# STM32MP25_CM33 register map
File version: 1.3
CPU: CM33 r0p1, little endian, MPU, FPU, vendor SysTick, 8 interrupt priority bits
Registers are 32-bit, read-write, reset 0x0 unless marked. A register's access mark holds for its fields unless they carry their own. Offsets are from the block's base; [hi:lo] are bit positions; lines under a group give offsets from that group; {n}, {i} and the like mark numbered series; 'fields as' and 'values as' point back to an identical list.

## DDRPHYC (part 2 of 2) — DDRPHYC address block description
Base 0x48C00000
Same registers: DDRPHYC_S 0x58C00000
0x80170 DDRPHYC_MASTER0_MEMALERTCONTROL2 — DDRPHYC MemAlert receiver configuration register 2
  [0] MALERTSYNCBYPASS — This bit is programmed as follows:
    0=The phy drives dfi_alert_n with a synchronized value of the ALERT_N receiver; 1=The phy drives dfi_alert_n with the asynchronous value of the ALERT_N receiver
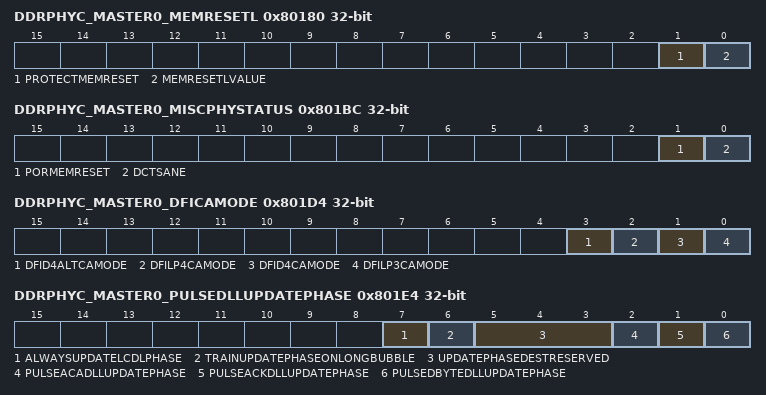
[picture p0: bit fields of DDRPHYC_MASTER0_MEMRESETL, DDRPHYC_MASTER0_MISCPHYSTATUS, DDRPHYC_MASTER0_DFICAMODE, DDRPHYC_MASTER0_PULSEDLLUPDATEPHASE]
0x80180 DDRPHYC_MASTER0_MEMRESETL — DDRPHYC protection and control of BP_MemReset_L register
  [1] PROTECTMEMRESET — Controls the MemResetL output of the PHY.
  [0] MEMRESETLVALUE — Controls the MemResetL output of the PHY.
0x801B8 DDRPHYC_MASTER0_PUBMODE — DDRPHYC PUBMODE - HWT Mux select register
  [0] HWTMEMSRC — When this bit is set, the mux that switches between DCT and HWT for the source of memory transactions is switched to HWT.
    0=Control to the DCT; 1=Control to the HWT
0x801BC DDRPHYC_MASTER0_MISCPHYSTATUS ro reset not defined — DDRPHYC misc PHY status bits register
  [1] PORMEMRESET — Returns the active-high value used by the custom circuit which drives the memory reset signal.
  [0] DCTSANE — Returns the status of the custom circuit which protects the MemResetL output of the PHY on the initial power-on or reset.
    0=Hardware controls the MemResetL output; 1=The memory reset is being controlled by MEMRESESETLVALUE and ProtectMemReset or dfi_reset_n
0x801C0 DDRPHYC_MASTER0_CORELOOPBACKSEL — DDRPHYC CoreLoopbackSel register
  [0] CORELOOPBACKSEL — This bit is controlled by the PHY test firmware.
0x801C4 DDRPHYC_MASTER0_DLLTRAINPARAM reset 0x2 — DDRPHYC DLL various training parameters register
  [1:0] EXTENDPHDTIME — Used by the PHY firmware locking the LCDL delay cells
0x801D0 DDRPHYC_MASTER0_HWTLPCSENBYPASS — DDRPHYC HwtLpCsEnBypass register
  [0] HWTLPCSENBYPASS — When set, this bit disables LpCsEn function for LPDDR4.
0x801D4 DDRPHYC_MASTER0_DFICAMODE — DDRPHYC DFI command/address mode register
  [3] DFID4ALTCAMODE — DDR4-Alt mode enable (only available in certain configurations)
    0=D4-Alt mode disabled; 1=D4-Alt mode enabled
  [2] DFILP4CAMODE — LP4 mode enable
    0=LP4 mode disabled; 1=LP4 mode enabled
  [1] DFID4CAMODE — DDR4 mode enable
    0=D4 mode disabled; 1=D4 mode enabled
  [0] DFILP3CAMODE — Reserved, must be kept at reset value.
0x801E0 DDRPHYC_MASTER0_DLLCONTROL reset 0x3 — DDRPHYC DLL lock state machine control register
  [0] DLLRESETRELOCK — Used to reset the DDL/LCDL lock state machine
0x801E4 DDRPHYC_MASTER0_PULSEDLLUPDATEPHASE — DDRPHYC DLL update phase control register
  [7] ALWAYSUPDATELCDLPHASE — Causes each new operation to reload the LcdlPhase, and increases bubbles.
  [6] TRAINUPDATEPHASEONLONGBUBBLE — Causes LongBubble to update the DBYTE and ANIB LDCL phase.
  [5:3] UPDATEPHASEDESTRESERVED — reserved, not used
  [2] PULSEACADLLUPDATEPHASE — Causes an AC module CA (command/address/cke/odt) DLL phase update.
  [1] PULSEACKDLLUPDATEPHASE — Causes an AC module CK (memck) DLL phase update.
  [0] PULSEDBYTEDLLUPDATEPHASE — Causes a LongBubble to the DBYTE modules, which causes an update of the DBYTE module DLLs (tx,rxen,rxclk).
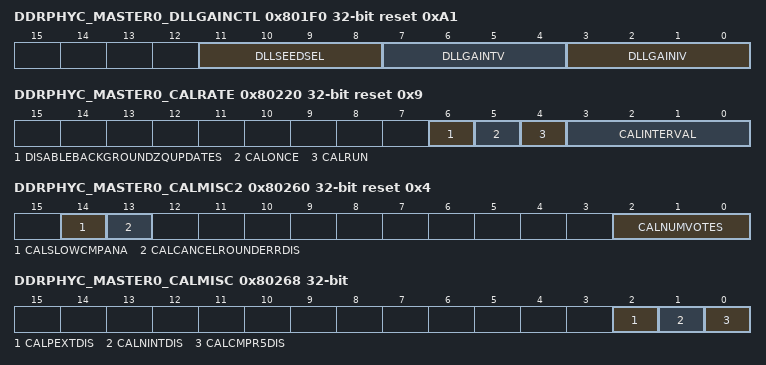
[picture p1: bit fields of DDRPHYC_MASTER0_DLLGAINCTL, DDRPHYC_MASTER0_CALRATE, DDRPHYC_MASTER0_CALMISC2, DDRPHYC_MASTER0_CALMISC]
0x801F0 DDRPHYC_MASTER0_DLLGAINCTL reset 0xA1 — DDRPHYC DLL gain control register
  [11:8] DLLSEEDSEL — Reserved, must be configured to be 0.
  [7:4] DLLGAINTV — Terminal value of DllGain (value in effect when locking is done), and value used for maintaining lock (tracking pclk variation)
  [3:0] DLLGAINIV — Initial value of DllGain
0x80220 DDRPHYC_MASTER0_CALRATE reset 0x9 — DDRPHYC impedance calibration control register
  [6] DISABLEBACKGROUNDZQUPDATES — Reserved for debug only
  [5] CALONCE — The setting of this bit changes the behavior of CALRUN.
    0=The calibration proceeds at the rate determined by CALINTERVAL[3:0]; 1=The 0->1 transition of CALRUN causes a single iteration of the calibration sequence to occur
  [4] CALRUN — This bit is programmed as follows:
    0=The calibrator does not run; 1=A calibration sequence is triggered by the 0->1 transition of this bit, as determined by CALONCE
  [3:0] CALINTERVAL — Interval between successive calibrations
    0=0 ms (continuous); 1=0; 2=0; 3=1 ms; 4=2 ms; 6=4 ms; 7=8 ms; 8=10 ms; 9=20 ms
0x80224 DDRPHYC_MASTER0_CALZAP — DDRPHYC CalZap register
  [0] CALZAP — This bit is written by the PIE, and the data in here are overwritten.
0x8022C DDRPHYC_MASTER0_PSTATE reset 0xC — DDRPHYC PState register
  [3:0] PSTATE — This bit field is written by the PIE, and the data in here are overwritten.
    0=PState P0; 12=LP2; 15=LP3
0x80234 DDRPHYC_MASTER0_PLLOUTGATECONTROL — DDRPHYC PLL output control register
  [0] PCLKGATEEN — Reserved.
0x80240 DDRPHYC_MASTER0_PORCONTROL — DDRPHYC PMU power-on reset control register
  [0] PLLDLLLOCKDONE — This bit is set by the PIE during execution, and cleared on PHY reset, or on power cycle.
0x8025C DDRPHYC_MASTER0_CALBUSY ro reset not defined — DDRPHYC CalBusy register
  [0] CALBUSY — Read 1 if the calibrator is actively calibrating.
0x80260 DDRPHYC_MASTER0_CALMISC2 reset 0x4 — DDRPHYC misc impedance calibration control register
  [14] CALSLOWCMPANA — When set, this bit doubles the time allowed for the analog comparator cell to settle before sampling begins.
  [13] CALCANCELROUNDERRDIS — The PEXT and NINT calibration results naturally include a rounding error which manifests as a change of impedance at the pad.
  [2:0] CALNUMVOTES — This bit field controls the number of consecutive comparator output bits over which majority voting is done.
    0=1; 1=9; 2=17; 3=33; 4=65 (default); 5=129; 6=193; 7=255
0x80268 DDRPHYC_MASTER0_CALMISC — DDRPHYC controls for disabling the impedance calibration of certain target register
  [2] CALPEXTDIS — Setting this bit prevents the calibration engine from overwriting TXCALBINP and TXCALTHP with an automatically generated value, in which case a value must be supplied by software.
  [1] CALNINTDIS — Setting this bit prevents the calibration engine from overwriting TXCALBIN and TXCALTHN with an automatically generated value, in which case a value must be supplied by software.
  [0] CALCMPR5DIS — Setting this bit prevents the calibration engine from using the result from the CALCMPR5 stage of calibration.
0x8026C DDRPHYC_MASTER0_CALVREFS reset 0x2 — DDRPHYC CalVRef register
  [1:0] CALVREFS — This bit field drives the Cmpdig_CalRef pin of the cmpana cell at various stages of calibration.
    2=50% Vless thansub>REFless than/sub> (default)
0x80270 DDRPHYC_MASTER0_CALCMPR5 ro reset not defined — DDRPHYC CalCmpr5 register
  [7:0] CALCMPR5 — Offset-compensated DAC code for the cmpana circuit
0x80274 DDRPHYC_MASTER0_CALNINT ro reset not defined — DDRPHYC impedance calibration NInt control register
  [4:0] CALNINTTHB — Number of thermometer bits which are set
0x80278 DDRPHYC_MASTER0_CALPEXT ro reset not defined — DDRPHYC impedance calibration PExt control register
  [4:0] CALPEXTTHB — Number of thermometer bits which are set
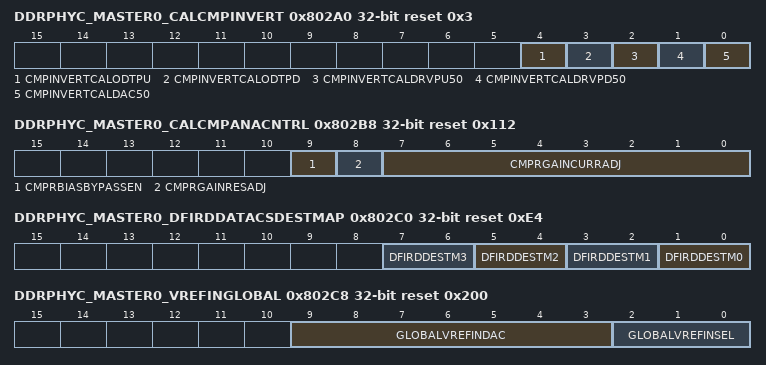
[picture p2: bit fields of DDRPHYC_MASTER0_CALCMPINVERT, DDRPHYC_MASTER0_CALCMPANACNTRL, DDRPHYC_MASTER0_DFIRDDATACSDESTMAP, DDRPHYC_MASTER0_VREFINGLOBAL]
0x802A0 DDRPHYC_MASTER0_CALCMPINVERT reset 0x3 — DDRPHYC impedance calibration Cmp invert control register
  [4] CMPINVERTCALODTPU — Impedance calibration Cmp invert control
  [3] CMPINVERTCALODTPD — Impedance calibration Cmp invert control
  [2] CMPINVERTCALDRVPU50 — Impedance calibration Cmp invert control
  [1] CMPINVERTCALDRVPD50 — Impedance calibration Cmp invert control
  [0] CMPINVERTCALDAC50 — calibration Cmp invert control
0x802B8 DDRPHYC_MASTER0_CALCMPANACNTRL reset 0x112 — DDRPHYC impedance calibration Cmpana control register
  [9] CMPRBIASBYPASSEN — Impedance calibration Cmpana control
  [8] CMPRGAINRESADJ — Impedance calibration Cmpana control
  [7:0] CMPRGAINCURRADJ — Impedance calibration Cmpana control
0x802C0 DDRPHYC_MASTER0_DFIRDDATACSDESTMAP reset 0xE4 — DDRPHYC maps dfi_rddata_cs_n to destination dimm timing group register
  [2n+1:2n] DFIRDDESTM{n} (n=0..3) — Maps dfi_rddata_cs_n[{n}] to destination DfiRdDestm{n} timing.
0x802C8 DDRPHYC_MASTER0_VREFINGLOBAL reset 0x200 — PHY global VREF controls register
  [9:3] GLOBALVREFINDAC — DAC code for internal Vless thansub>REFless than/sub> generation
  [2:0] GLOBALVREFINSEL — [1:0] controls the mode of the PHY Vless thansub>REFless than/sub> DAC and the BP_VREF pin.
    0=PHY Vless thansub>REFless than/sub> DAC range0 -- BP_VREF = Hi-Z; 2=PHY Vless thansub>REFless than/sub> DAC range0 -- BP_VREF connected to PLL analog bus; 3=PHY Vless thansub>REFless than/sub> DAC range0 -- BP_VREF connected to PHY Vless thansub>REFless than/sub> DAC
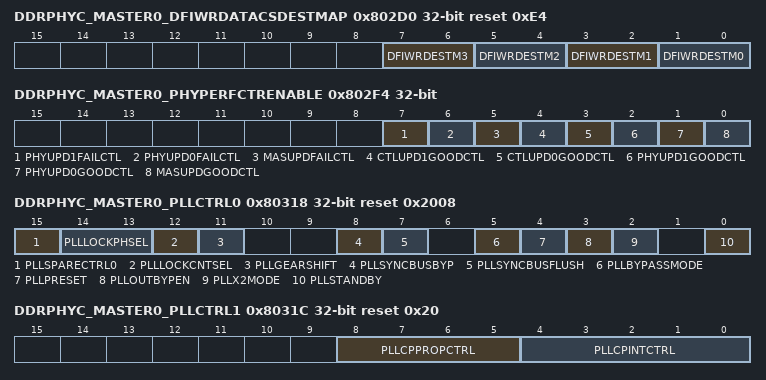
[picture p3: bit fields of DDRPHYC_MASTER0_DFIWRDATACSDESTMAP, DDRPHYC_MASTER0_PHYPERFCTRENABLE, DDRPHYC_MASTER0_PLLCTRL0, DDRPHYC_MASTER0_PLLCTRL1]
0x802D0 DDRPHYC_MASTER0_DFIWRDATACSDESTMAP reset 0xE4 — DDRPHYC maps dfi_rddata_cs_n to destination dimm timing group register
  [7:6] DFIWRDESTM3 — Maps dfi_wrdata_cs_n[3] to destination DfiWrDestm3 timing (use register Tx[Dq,Dqs]DlyTg3)
  [5:4] DFIWRDESTM2 — Maps dfi_wrdata_cs_n[2] to destination DfiWrDestm2 timing
  [3:2] DFIWRDESTM1 — Maps dfi_wrdata_cs_n[1] to destination DfiWrDestm1 timing
  [1:0] DFIWRDESTM0 — Maps dfi_wrdata_cs_n[0] to destination DfiWrDestm0 timing
0x802D4 DDRPHYC_MASTER0_MASUPDGOODCTR ro reset not defined — DDRPHYC MasUpdGoodCtr register
  [15:0] MASUPDGOODCTR — This bit field increments whenever the memory controller acknowledges a PHY master interface request (a request for the PHY) to take over the DFI for PPT (as per section 11 of the Preliminary DFI 4.
0x802D8 DDRPHYC_MASTER0_PHYUPD0GOODCTR ro reset not defined — DDRPHYC PhyUpd0GoodCtr register
  [15:0] PHYUPD0GOODCTR — This bit field increments whenever the memory controller acknowledges a PHY-initiated DFI0 interface update request.
0x802DC DDRPHYC_MASTER0_PHYUPD1GOODCTR ro reset not defined — DDRPHYC PhyUpd1GoodCtr register
  [15:0] PHYUPD1GOODCTR — This bit field increments whenever the memory controller acknowledges a PHY-initiated DFI1 interface update request.
0x802E0 DDRPHYC_MASTER0_CTLUPD0GOODCTR ro reset not defined — DDRPHYC CtlUpd0GoodCtr register
  [15:0] CTLUPD0GOODCTR — This bit field increments whenever the PHY acknowledges a memory controller-initiated DFI0 interface update request.
0x802E4 DDRPHYC_MASTER0_CTLUPD1GOODCTR ro reset not defined — DDRPHYC CtlUpd1GoodCtr register
  [15:0] CTLUPD1GOODCTR — This bit field increments whenever the PHY acknowledges a memory controller-initiated DFI1 interface update request.
0x802E8 DDRPHYC_MASTER0_MASUPDFAILCTR ro reset not defined — DDRPHYC MasUpdFailCtr register
  [15:0] MASUPDFAILCTR — This bit field increments whenever the PHY asserts a PHY master interface request, but the memory controller does not acknowledge the request within the allowed interval (as per section 11 of the Preliminary DFI 4.
0x802EC DDRPHYC_MASTER0_PHYUPD0FAILCTR ro reset not defined — DDRPHYC PhyUpd0FailCtr register
  [15:0] PHYUPD0FAILCTR — This bit field increments whenever the PHY asserts a DFI0 interface update request, but the memory controller does not acknowledge the request within the allowed interval (as per section 11 of the Preliminary DFI 4.
0x802F0 DDRPHYC_MASTER0_PHYUPD1FAILCTR ro reset not defined — DDRPHYC PhyUpd1FailCtr register
  [15:0] PHYUPD1FAILCTR — This bit field increments whenever the PHY asserts a DFI1 interface update request, but the memory controller does not acknowledge the request within the allowed interval (as per section 11 of the Preliminary DFI 4.
0x802F4 DDRPHYC_MASTER0_PHYPERFCTRENABLE — DDRPHYC performance counter enable register
  [7] PHYUPD1FAILCTL — PHYUPD1FAILCTLR enable
  [6] PHYUPD0FAILCTL — PHYUPD0FAILCTLR enable
  [5] MASUPDFAILCTL — MASUPDFAILCTLR enable
  [4] CTLUPD1GOODCTL — CTLUPD1GOODCTLR enable
  [3] CTLUPD0GOODCTL — CTLUPD0GOODCTLR enable
  [2] PHYUPD1GOODCTL — PHYUPD1GOODCTLR enable
  [1] PHYUPD0GOODCTL — PHYUPD0GOODCTLR enable
  [0] MASUPDGOODCTL — MASUPDGOODCTLR enable
0x8030C DDRPHYC_MASTER0_PLLPWRDN reset 0x1 — DDRPHYC PllPwrDn register
  [0] PLLPWRDN — This bit is written by the PIE, and the data in here are overwritten.
0x80314 DDRPHYC_MASTER0_PLLCTRL2 reset 0x19 — DDRPHYC PState dependent PLL control 2 register
  [4:0] PLLFREQSEL — Adjusts the loop parameters to compensate for different VCO bias points, and input/output clock division ratios.
0x80318 DDRPHYC_MASTER0_PLLCTRL0 reset 0x2008 — DDRPHYC PLL control 0 register
  [15] PLLSPARECTRL0 — Spare bits for PLL control
  [14:13] PLLLOCKPHSEL — Lock detect phase selection
    0=Test mode reduced lock window; 1=Default operation phase lock; 2=Test mode (mismatch check); 3=Test mode (+80ps window)
  [12] PLLLOCKCNTSEL — Lock detect counter selection
    0=Normal lock detector behavior phase lock; 1=Test mode (shorten lock cycle count 16->8)
  [11] PLLGEARSHIFT — PLL fast re-locking mode
    0=Normal mode (default); 1=Fast relock gear
  [8] PLLSYNCBUSBYP — When asserted, bypasses the Pll SyncPulse, and uses a synchronizer of the same latency.
  [7] PLLSYNCBUSFLUSH — Used to flush the syncbus logic of the PLL during PHY initialization or LP3 exit sequence.
  [5] PLLBYPASSMODE — PLL bypass clock mux control
  [4] PLLPRESET — PLL preset mode
  [3] PLLOUTBYPEN — Controls the anti-glitch mux on the pllout_x1x2x4 path.
    1=pllout_x1x2x4 = byp_pllin_x1; 0=pllout_x1x2x4 = VCO (SCD) (selected by x2_mode)
  [2] PLLX2MODE — Connects to x2_mode pins of PLL (pllout_x4x2 output frequency selection).
    0=PLOUT_X4X2 output = 4*pllin_x1 frequency; 1=PLOUT_X4X2 output = 2*pllin_x1 frequency
  [0] PLLSTANDBY — Connects directly to standby pin of the PLL.
0x8031C DDRPHYC_MASTER0_PLLCTRL1 reset 0x20 — DDRPHYC PState dependent PLL control 1 register
  [8:5] PLLCPPROPCTRL — Connects directly to cp_prop_cntrlless than3:0> of the PLL.
  [4:0] PLLCPINTCTRL — Connects directly to cp_int_cntrlless than4:0> in the PLL.
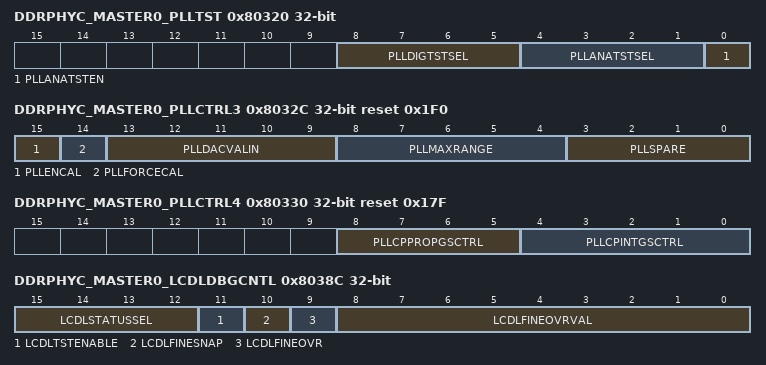
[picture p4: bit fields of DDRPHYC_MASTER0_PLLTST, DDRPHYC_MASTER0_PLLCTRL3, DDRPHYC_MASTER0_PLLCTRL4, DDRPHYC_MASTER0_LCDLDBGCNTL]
0x80320 DDRPHYC_MASTER0_PLLTST — DDRPHYC PLL testing control register
  [8:5] PLLDIGTSTSEL — Digital test mux select
  [4:1] PLLANATSTSEL — Connects directly to pll_ana_test_selless than3:0> of PLL.
    0=Hi-Z: This code must be set when the PLL is in normal use or when the digital test port is being used for accurate timing measurements; 1=core: Override vmarg_ext with analog pin; 2=core: Override regulator input with analog pin; 3=core: Observe gd voltage on analog test pin; 4=core: Observe vp voltage on analog test pin; 5=core: Observe vph voltage on analog test pin; 6=core: Observe vreg_cp voltage on analog test pin; 7=core: Observe v2i current (~10uA) on analog test pin; 8=core: Observe vreg_v2i voltage on analog test pin; 9=core: Observe vbp voltage from current source on analog pin; 10=core: Observe vbn voltage from current source on analog pin; 11=core: NC; 12=core: NC; 13=VSS: 0v probe IR drop test; 14=VP: Core supply probe SCD IR drop test; 15=VPH: Core supply probe Refdiv IR drop test
  [0] PLLANATSTEN — Analog test port enable
    0=Analog test port disabled (hi-Z); 1=Analog test port enabled
0x80324 DDRPHYC_MASTER0_PLLLOCKSTATUS ro reset not defined — DDRPHYC PllLockStatus register
  [0] PLLLOCKSTATUS — Directly connected to the pll_Lock output
0x80328 DDRPHYC_MASTER0_PLLTESTMODE reset 0x124 — DDRPHYC PII TestMode register
  [15:0] PLLTESTMODE — Default values for this bit field must be used unless directed otherwise by Synopsys.
0x8032C DDRPHYC_MASTER0_PLLCTRL3 reset 0x1F0 — DDRPHYC PLL control 3 register
  [15] PLLENCAL
    0=The calibration does not run; 1=The calibration runs at standby rising edge
  [14] PLLFORCECAL — Connects directly to force_cal of PLL.
    0=Previous stored value used; 1=Forces the calibration code dacval_inless than4:0> to be used at preset mode
  [13:9] PLLDACVALIN — Connects directly to dacval_inless than4:0> of PLL.
  [8:4] PLLMAXRANGE — Connects directly to maxrange of PLL.
  [3:0] PLLSPARE — Spare bits
0x80330 DDRPHYC_MASTER0_PLLCTRL4 reset 0x17F — DDRPHYC PState dependent PLL control 4 register
  [8:5] PLLCPPROPGSCTRL — Connects directly to cp_prop_gs_cntrlless than3:0> of PLL.
  [4:0] PLLCPINTGSCTRL — Connects directly to cp_int_gs_cntrlless than4:0> in PLL.
0x80334 DDRPHYC_MASTER0_PLLENDOFCAL ro reset not defined — DDRPHYC PllEndofCal register
  [0] PLLENDOFCAL — Directly connected to the PLL eoc output.
0x80338 DDRPHYC_MASTER0_PLLSTANDBYEFF ro reset not defined — DDRPHYC PllStandbyEff register
  [0] PLLSTANDBYEFF — State off PLL standby (in PHY LP2 states)
0x8033C DDRPHYC_MASTER0_PLLDACVALOUT ro reset not defined — DDRPHYC PllDacValOut register
  [4:0] PLLDACVALOUT — Directly connected to the PLL dacval_out output.
0x8038C DDRPHYC_MASTER0_LCDLDBGCNTL — DDRPHYC LcdlDbgCntl register
  [15:12] LCDLSTATUSSEL — Selection of the LCDL status
    15=lcdl_rxclk1t reserved; 14=lcdl_rxclk0t reserved; 13=lcdl_rxclk1c reserved; 12=lcdl_rxclk0c reserved; 11=lcdl_rxen1 anib11-tx; 10=lcdl_rxen0 anib10-tx; 9=lcdl_txln9 (dqs-lower) anib9-tx; 8=lcdl_txln8 (dm/dqs-upper) anib8-tx; {v}=lcdl_txln{v} (dq{v}) anib{v}-tx (v=0..7)
  [11] LCDLTSTENABLE — Debug/test operations enable
  [10] LCDLFINESNAP — Latch enable for reading the present LCDL 1UI estimate code in LCDLFINESNAPVAL, and the present phase-detector value in LCDLPHDSNAPVAL.
  [9] LCDLFINEOVR — Forces the value of the present LCDL 1UI estimate code to be LCDLFINEOVRVAL for all LCDLs.
  [8:0] LCDLFINEOVRVAL — Value forced as the initial value while LCDLTSTENABLE = 1 and LCDLFINEOVR
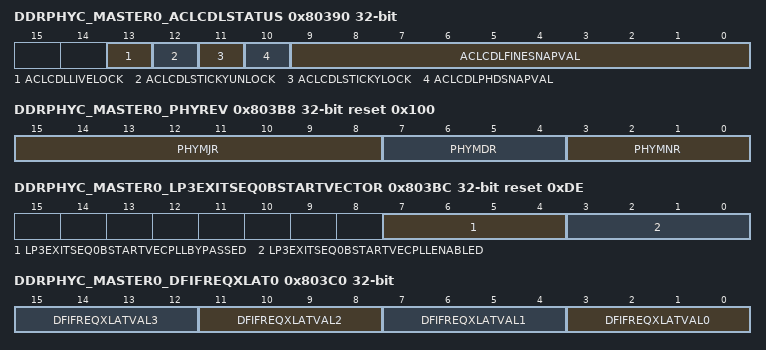
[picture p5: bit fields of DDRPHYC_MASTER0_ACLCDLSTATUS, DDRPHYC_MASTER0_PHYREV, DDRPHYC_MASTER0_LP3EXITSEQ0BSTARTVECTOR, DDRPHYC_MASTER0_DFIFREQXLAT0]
0x80390 DDRPHYC_MASTER0_ACLCDLSTATUS ro reset not defined — DDRPHYC Debug status of the DBYTE LCDL register
  [13] ACLCDLLIVELOCK — Present value of whether the LCDL is locked
  [12] ACLCDLSTICKYUNLOCK — Latched value of whether the LCDL ever lost lock after the assertion of LCDLTSTENABLE.
  [11] ACLCDLSTICKYLOCK — Latched value of whether the LCDL ever achieved lock after the assertion of LCDLTSTENABLE.
  [10] ACLCDLPHDSNAPVAL — Value of the LCDL phase-detector output, latched by pulse on LCDLFINESNAP, while LCDLTSTENABLE = 1.
  [9:0] ACLCDLFINESNAPVAL — Value of the LCDL 1UI estimate code, latched by pulse on LCDLFINESNAP, while LCDLTSTENABLE = 1.
0x803B4 DDRPHYC_MASTER0_CUSTPHYREV ro reset not defined — DDRPHYC CUSTPHYREV register
  [5:0] CUSTPHYREV — Customer settable PHY version number
0x803B8 DDRPHYC_MASTER0_PHYREV ro reset 0x100 — DDRPHYC PHYREV register
  [15:8] PHYMJR — PHY major revision
  [7:4] PHYMDR — PHY moderate revision
  [3:0] PHYMNR — PHY minor update
0x803BC DDRPHYC_MASTER0_LP3EXITSEQ0BSTARTVECTOR reset 0xDE — DDRPHYC Start vector value for LP3-exit or init PIE sequence register
  [7:4] LP3EXITSEQ0BSTARTVECPLLBYPASSED — PIE start vector value to be used for LP3 exit or init and target P-state has PLL bypassed
  [3:0] LP3EXITSEQ0BSTARTVECPLLENABLED — PIE start vector value to be used for LP3 exit or init and target P-state has PLL enabled
0x803C0 DDRPHYC_MASTER0_DFIFREQXLAT0 — DDRPHYC DFI frequency translation 0 register
  [4n+3:4n] DFIFREQXLATVAL{n} (n=0..3) — Sequencer start vector used when dfi_freq value is {n}
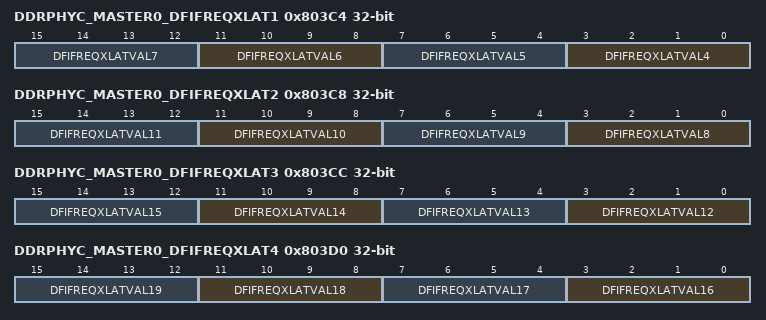
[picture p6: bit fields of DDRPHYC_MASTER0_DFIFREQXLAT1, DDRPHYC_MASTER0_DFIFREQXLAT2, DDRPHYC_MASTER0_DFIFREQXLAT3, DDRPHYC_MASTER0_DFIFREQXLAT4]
0x803C4 DDRPHYC_MASTER0_DFIFREQXLAT1 — DDRPHYC DFI frequency translation 1 register
  [4n-13:4n-16] DFIFREQXLATVAL{n} (n=4..7) — Sequencer start vector used when dfi_freq value is {n}
0x803C8 DDRPHYC_MASTER0_DFIFREQXLAT2 — DDRPHYC DFI frequency translation 2 register
  [4n-29:4n-32] DFIFREQXLATVAL{n} (n=8..11) — Sequencer start vector used when dfi_freq value is {n}
0x803CC DDRPHYC_MASTER0_DFIFREQXLAT3 — DDRPHYC DFI frequency translation 3 register
  [4n-45:4n-48] DFIFREQXLATVAL{n} (n=12..15) — Sequencer start vector used when dfi_freq value is {n}
0x803D0 DDRPHYC_MASTER0_DFIFREQXLAT4 — DDRPHYC DFI frequency translation 4 register
  [4n-61:4n-64] DFIFREQXLATVAL{n} (n=16..19) — Sequencer start vector used when dfi_freq value is {n}
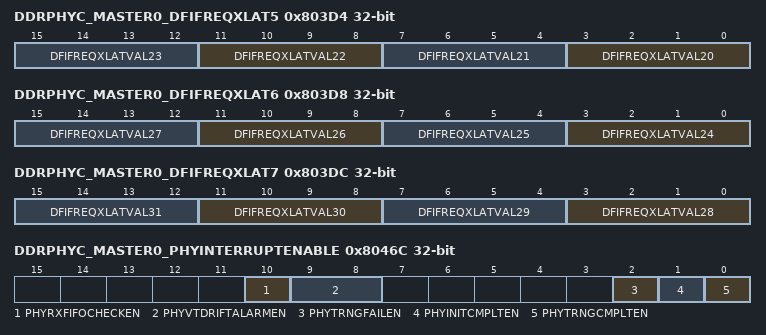
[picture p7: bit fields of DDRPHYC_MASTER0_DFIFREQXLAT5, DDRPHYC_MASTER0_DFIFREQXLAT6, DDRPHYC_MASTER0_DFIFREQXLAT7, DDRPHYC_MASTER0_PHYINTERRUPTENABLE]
0x803D4 DDRPHYC_MASTER0_DFIFREQXLAT5 — DDRPHYC DFI frequency translation 5 register
  [4n-77:4n-80] DFIFREQXLATVAL{n} (n=20..23) — Sequencer start vector used when dfi_freq value is {n}
0x803D8 DDRPHYC_MASTER0_DFIFREQXLAT6 — DDRPHYC DFI frequency translation 6 register
  [4n-93:4n-96] DFIFREQXLATVAL{n} (n=24..27) — Sequencer start vector used when dfi_freq value is {n}
0x803DC DDRPHYC_MASTER0_DFIFREQXLAT7 — DDRPHYC DFI frequency translation 7 register
  [4n-109:4n-112] DFIFREQXLATVAL{n} (n=28..31) — Sequencer start vector used when dfi_freq value is {n}
0x803E0 DDRPHYC_MASTER0_TXRDPTRINIT reset 0x1 — DDRPHYC TxRdPtrInit register
  [0] TXRDPTRINIT — This bit controls TxRdPtrInit, and is meant to be written by the PState sequencer as part of the power state switching sequence.
0x803E4 DDRPHYC_MASTER0_DFIINITCOMPLETE — DDRPHYC DfiInitComplete register
  [0] DFIINITCOMPLETE — This bit directly controls DfiInitComplete, and is meant to be written by the PState sequencer as part of the power state switching sequence.
0x803E8 DDRPHYC_MASTER0_DFIFREQRATIO reset 0x1 — DDRPHYC DfiFreqRatio register
  [1:0] DFIFREQRATIO — Ratio DfiCtlClk:MemClk
0x803EC DDRPHYC_MASTER0_RXFIFOCHECKS — DDRPHYC RxFifoCheck register
  [0] DOFREQUENTRXFIFOCHECKS
    0=Read data FIFO pointer consistency checks are performed only during sideband transactions (phyupd, ctrlupd, lp_data, phymstr), or when dfi_init_start is asserted; 1=Read data FIFO consistency checks are performed as when this bit is 0, and also at the beginning of each break in read data traffic from the DRAM
0x803FC DDRPHYC_MASTER0_MTESTDTOCTRL — DDRPHYC MTestCombo output enable on core-side copy register
  [0] MTESTDTOEN — This bit is programmed as follows:
0x80400 DDRPHYC_MASTER0_MAPCAA0TODFI — DDRPHYC MapCAA[0to7]toDfi register
  [3:0] MAPCAATODFI — For LPDDR4 application, this bit field maps a dfi0_address to CAA x.
0x80404 DDRPHYC_MASTER0_MAPCAA1TODFI reset 0x1 — DDRPHYC MapCAA[0to7]toDfi register
  fields as DDRPHYC_MASTER0_MAPCAA0TODFI
0x80408 DDRPHYC_MASTER0_MAPCAA2TODFI reset 0x2 — DDRPHYC MapCAA[0to7]toDfi register
  fields as DDRPHYC_MASTER0_MAPCAA0TODFI
0x8040C DDRPHYC_MASTER0_MAPCAA3TODFI reset 0x3 — DDRPHYC MapCAA[0to7]toDfi register
  fields as DDRPHYC_MASTER0_MAPCAA0TODFI
0x80410 DDRPHYC_MASTER0_MAPCAA4TODFI reset 0x4 — DDRPHYC MapCAA[0to7]toDfi register
  fields as DDRPHYC_MASTER0_MAPCAA0TODFI
0x80414 DDRPHYC_MASTER0_MAPCAA5TODFI reset 0x5 — DDRPHYC MapCAA[0to7]toDfi register
  fields as DDRPHYC_MASTER0_MAPCAA0TODFI
0x80418 DDRPHYC_MASTER0_MAPCAA6TODFI reset 0x6 — DDRPHYC MapCAA[0to7]toDfi register
  fields as DDRPHYC_MASTER0_MAPCAA0TODFI
0x8041C DDRPHYC_MASTER0_MAPCAA7TODFI reset 0x7 — DDRPHYC MapCAA[0to7]toDfi register
  fields as DDRPHYC_MASTER0_MAPCAA0TODFI
0x80440 DDRPHYC_MASTER0_MAPCAB0TODFI — DDRPHYC MapCAB[0to7]toDfi register
  [3:0] MAPCABTODFI — For LPDDR4 application, this bit field maps a dfi1_address to CAB x.
0x80444 DDRPHYC_MASTER0_MAPCAB1TODFI reset 0x1 — DDRPHYC MapCAB[0to7]toDfi register
  fields as DDRPHYC_MASTER0_MAPCAB0TODFI
0x80448 DDRPHYC_MASTER0_MAPCAB2TODFI reset 0x2 — DDRPHYC MapCAB[0to7]toDfi register
  fields as DDRPHYC_MASTER0_MAPCAB0TODFI
0x8044C DDRPHYC_MASTER0_MAPCAB3TODFI reset 0x3 — DDRPHYC MapCAB[0to7]toDfi register
  fields as DDRPHYC_MASTER0_MAPCAB0TODFI
0x80450 DDRPHYC_MASTER0_MAPCAB4TODFI reset 0x4 — DDRPHYC MapCAB[0to7]toDfi register
  fields as DDRPHYC_MASTER0_MAPCAB0TODFI
0x80454 DDRPHYC_MASTER0_MAPCAB5TODFI reset 0x5 — DDRPHYC MapCAB[0to7]toDfi register
  fields as DDRPHYC_MASTER0_MAPCAB0TODFI
0x80458 DDRPHYC_MASTER0_MAPCAB6TODFI reset 0x6 — DDRPHYC MapCAB[0to7]toDfi register
  fields as DDRPHYC_MASTER0_MAPCAB0TODFI
0x8045C DDRPHYC_MASTER0_MAPCAB7TODFI reset 0x7 — DDRPHYC MapCAB[0to7]toDfi register
  fields as DDRPHYC_MASTER0_MAPCAB0TODFI
0x8046C DDRPHYC_MASTER0_PHYINTERRUPTENABLE — DDRPHYC interrupt enable register
  [all] fields
    0=Interrupt not enabled; 1=Interrupt enabled
  [10] PHYRXFIFOCHECKEN — Rx FIFO pointer check interrupt enable
  [9:8] PHYVTDRIFTALARMEN — PHY VT drift alarm interrupt enable
  [2] PHYTRNGFAILEN — PHY training failure interrupt enable
  [1] PHYINITCMPLTEN — PHY initialization complete interrupt enable
  [0] PHYTRNGCMPLTEN — PHY training complete interrupt enable
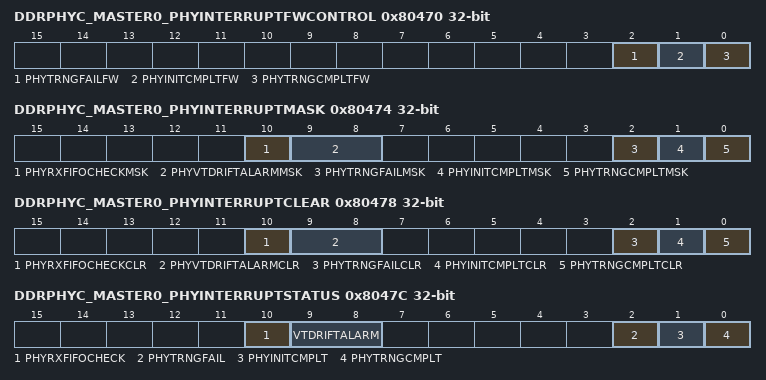
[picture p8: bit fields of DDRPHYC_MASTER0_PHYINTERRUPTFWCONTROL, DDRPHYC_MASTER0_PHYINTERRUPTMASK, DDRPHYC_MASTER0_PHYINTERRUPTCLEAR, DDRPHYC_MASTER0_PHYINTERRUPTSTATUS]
0x80470 DDRPHYC_MASTER0_PHYINTERRUPTFWCONTROL — DDRPHYC interrupt firmware control register
  [all] fields
    0=Interrupt not asserted; 1=Interrupt asserted
  [2] PHYTRNGFAILFW — PHY training failure firmware interrupt
  [1] PHYINITCMPLTFW — PHY initialization complete firmware interrupt
  [0] PHYTRNGCMPLTFW — PHY training complete firmware interrupt
0x80474 DDRPHYC_MASTER0_PHYINTERRUPTMASK — DDRPHYC interrupt mask register
  [all] fields
    0=Interrupt not masked; 1=Interrupt masked
  [10] PHYRXFIFOCHECKMSK — Mask for the Rx FIFO pointers check interrupt
  [9:8] PHYVTDRIFTALARMMSK — Mask for the PHY VT drift alarm interrupts
  [2] PHYTRNGFAILMSK — Mask for the PHY training failure interrupt
  [1] PHYINITCMPLTMSK — Mask for the PHY initialization complete interrupt
  [0] PHYTRNGCMPLTMSK — Mask for the PHY training complete interrupt
0x80478 DDRPHYC_MASTER0_PHYINTERRUPTCLEAR — DDRPHYC interrupt clear register
  [all] fields
    0=Interrupt not affected; 1=Interrupt cleared
  [10] PHYRXFIFOCHECKCLR — Rx FIFO pointers check interrupt clear
  [9:8] PHYVTDRIFTALARMCLR — PHY VT drift alarm interrupt clear
  [2] PHYTRNGFAILCLR — PHY training failure interrupt clear
  [1] PHYINITCMPLTCLR — PHY initialization complete interrupt clear
  [0] PHYTRNGCMPLTCLR — PHY training complete interrupt clear
0x8047C DDRPHYC_MASTER0_PHYINTERRUPTSTATUS ro reset not defined — DDRPHYC interrupt status register
  [all] fields
    0=Interrupt not enabled and asserted; 1=Interrupt enabled and asserted
  [10] PHYRXFIFOCHECK — A mechanism in the PHY checks the read FIFO pointers for consistency at times they are idle.
  [9:8] VTDRIFTALARM — PHY VT drift alarm interrupt
  [2] PHYTRNGFAIL — PHY training failure interrupt
  [1] PHYINITCMPLT — PHY initialization complete interrupt
  [0] PHYTRNGCMPLT — PHY training complete interrupt
{0x80480+4i} DDRPHYC_MASTER0_HWTSWIZZLEHWTADDRESS{i} (i=0..17) — DDRPHYC HwtSwizzleHwtAddress0 register
  [4:0] HWTSWIZZLEHWTADDRESS — This bit field is used in DDR3/DDR4 mode where a user has remapped the DFI inputs to
    0=No remapping; 1=hwt_address[0]; 2=hwt_address[9]; 3=hwt_address[10]
0x804C4 DDRPHYC_MASTER0_HWTSWIZZLEHWTACTN (alternate view of DDRPHYC_MASTER0_HWTSWIZZLEHWTADDRESS17) — DDRPHYC HwtSwizzleHwtActN register
  [4:0] HWTSWIZZLEHWTACTN — See HWTSWIZZLEHWTADDRESS0[4:0] description for details.
{0x804C8+4i} DDRPHYC_MASTER0_HWTSWIZZLEHWTBANK{i} (i=0..2) — DDRPHYC HwtSwizzleHwtBank{i} register
  [4:0] HWTSWIZZLEHWTBANK{i} — See HWTSWIZZLEHWTADDRESS0[4:0] description for details.
0x804D4 DDRPHYC_MASTER0_HWTSWIZZLEHWTBG0 — DDRPHYC HwtSwizzleHwtBg0 register
  [4:0] HWTSWIZZLEHWTBG0 — See HWTSWIZZLEHWTADDRESS0[4:0] description for details.
0x804D8 DDRPHYC_MASTER0_HWTSWIZZLEHWTBG1 — DDRPHYC HwtSwizzleHwtBg1 register
  [4:0] HWTSWIZZLEHWTBG1 — See HWTSWIZZLEHWTADDRESS0[4:0] description for details.
0x804DC DDRPHYC_MASTER0_HWTSWIZZLEHWTCASN — DDRPHYC HwtSwizzleHwtCasN register
  [4:0] HWTSWIZZLEHWTCASN — See HWTSWIZZLEHWTADDRESS0[4:0] description for details.
0x804E0 DDRPHYC_MASTER0_HWTSWIZZLEHWTRASN — DDRPHYC HwtSwizzleHwtRasN register
  [4:0] HWTSWIZZLEHWTRASN — See HWTSWIZZLEHWTADDRESS0[4:0] description for details.
0x804E4 DDRPHYC_MASTER0_HWTSWIZZLEHWTWEN — DDRPHYC HwtSwizzleHwtWeN register
  [4:0] HWTSWIZZLEHWTWEN — See HWTSWIZZLEHWTADDRESS0[4:0] description for details.
0x804E8 DDRPHYC_MASTER0_HWTSWIZZLEHWTPARITYIN — DDRPHYC HwtSwizzleHwtParityIn register
  [4:0] HWTSWIZZLEHWTPARITYIN — See HWTSWIZZLEHWTADDRESS0[4:0] description for details.
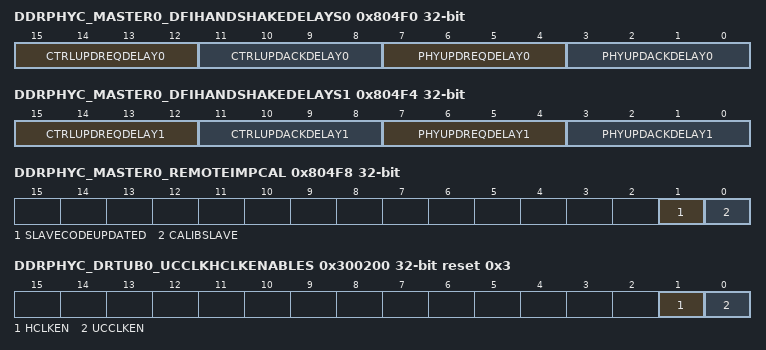
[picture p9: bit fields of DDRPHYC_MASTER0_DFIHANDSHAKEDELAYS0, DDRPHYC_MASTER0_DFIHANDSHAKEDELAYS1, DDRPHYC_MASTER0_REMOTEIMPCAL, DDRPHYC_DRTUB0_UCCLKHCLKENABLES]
0x804F0 DDRPHYC_MASTER0_DFIHANDSHAKEDELAYS0 — DDRPHYC small delays on handshake signals register 0
  [15:12] CTRLUPDREQDELAY0 — Adds 0-15 DfiClks of delay after the PHY completes all PHY update activities, before deasserting dfi0_ctrlupd_ack.
  [11:8] CTRLUPDACKDELAY0 — Adds 0-15 DfiClks of delay after dfi0_ctrlupd_req asserts, before the PHY takes any action.
  [7:4] PHYUPDREQDELAY0 — Adds 0-15 DfiClks of delay after the PHY completes all PHY update activities, before deasserting dfi0_phyupd_req.
  [3:0] PHYUPDACKDELAY0 — Adds 0-15 DfiClks of delay after dfi0_phyupd_ack asserts, before the PHY takes any action (such as starting DDL calibration).
0x804F4 DDRPHYC_MASTER0_DFIHANDSHAKEDELAYS1 — DDRPHYC small delays on handshake signals register 1
  [15:12] CTRLUPDREQDELAY1 — Adds 0-15 DfiClks of delay after the PHY completes all PHY update activities, before deasserting dfi1_ctrlupd_ack.
  [11:8] CTRLUPDACKDELAY1 — Adds 0-15 DfiClks of delay after dfi1_ctrlupd_req asserts, before the PHY takes any action.
  [7:4] PHYUPDREQDELAY1 — Adds 0-15 DfiClks of delay after the PHY completes all PHY update activities, before deasserting dfi1_phyupd_req.
  [3:0] PHYUPDACKDELAY1 — Adds 0-15 DfiClks of delay after dfi1_phyupd_ack asserts, before the PHY takes any action (such as starting DDL calibration).
0x804F8 DDRPHYC_MASTER0_REMOTEIMPCAL ro reset not defined — DDRPHYC remote impedance calibration status register
  [1] SLAVECODEUPDATED — - if DWC_DDRPHY_REMOTE_IMP_CAL is defined, this bit is set by hardware when
  [0] CALIBSLAVE — - if DWC_DDRPHY_REMOTE_IMP_CAL is defined, this bit is set by hardware when
0x2400A0 DDRPHYC_INITENG0_PHYINLP3 ro reset 0x1 — DDRPHYC PhyInLP3 register
  [0] PHYINLP3 — This bit is set by the PIE once the LP3 entry sequence is completed.
0x300200 DDRPHYC_DRTUB0_UCCLKHCLKENABLES reset 0x3 — DDRPHYC Ucclk and Hclk enable register
  [1] HCLKEN — When the training is complete (and assuming no further need for training hardware), this bit must be cleared to reduce power.
  [0] UCCLKEN — When the training is complete (and assuming no further need for the microcontroller), this bit must be cleared to reduce power.
0x300204 DDRPHYC_DRTUB0_CURPSTATE0B — DDRPHYC CurPstate0b register
  [3:0] CURPSTATE0B — PIE current PState
0x3003B4 DDRPHYC_DRTUB0_CUSTPUBREV ro reset not defined — DDRPHYC CUSTPUBREV register
  [5:0] CUSTPUBREV — Customer settable PUB version number
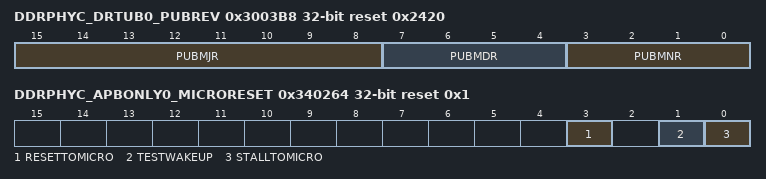
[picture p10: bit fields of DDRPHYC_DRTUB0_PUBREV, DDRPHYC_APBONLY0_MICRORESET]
0x3003B8 DDRPHYC_DRTUB0_PUBREV ro reset 0x2420 — DDRPHYC PUBREV register
  [15:8] PUBMJR — PUB major revision
  [7:4] PUBMDR — PUB moderate revision
  [3:0] PUBMNR — PUB minor revision
0x340000 DDRPHYC_APBONLY0_MICROCONTMUXSEL — DDRPHYC MicroContMuxSel register
  [0] MICROCONTMUXSEL — Controls access to the PHY configuration registers.
    1=Microcontroller/PIE has control of csr bus; 0=Microcontroller/PIE csr requests are ignored
0x340010 DDRPHYC_APBONLY0_UCTSHADOWREGS ro reset not defined — DDRPHYC PMU/controller protocol, controller read-only shadow register
  [0] UCTWRITEPROTSHADOW
    0=The PMU has a message for the user
0x3400C4 DDRPHYC_APBONLY0_DCTWRITEPROT reset 0x1 — DDRPHYC DctWriteProt register
  [0] DCTWRITEPROT — By clearing this bit, the user acknowledges the receipt of the message.
0x3400C8 DDRPHYC_APBONLY0_UCTWRITEONLYSHADOW ro reset not defined — DDRPHYC UctWriteOnlyShadow register
  [15:0] UCTWRITEONLYSHADOW — Used to pass the message ID for major messages, and to pass the lower 16 bits for streaming messages.
0x3400D0 DDRPHYC_APBONLY0_UCTDATWRITEONLYSHADOW ro reset not defined — DDRPHYC UctDatWriteOnlyShadow register
  [15:0] UCTDATWRITEONLYSHADOW — Used to pass the upper 16 bits for streaming messages.
0x3400DC DDRPHYC_APBONLY0_DFICFGRDDATAVALIDTICKS reset 0x6 — DDRPHYC DfiCfgRdDataValidTicks register
  [5:0] DFICFGRDDATAVALIDTICKS — Round trip delay of a register read access
0x340264 DDRPHYC_APBONLY0_MICRORESET reset 0x1 — DDRPHYC reset and clock shutdown control register
  [3] RESETTOMICRO — This bit is programmable as follows:
  [1] TESTWAKEUP — Reserved, must always be set to 0.
  [0] STALLTOMICRO — This bit is programmable as follows:
0x3403E8 DDRPHYC_APBONLY0_DFIINITCOMPLETESHADOW ro reset not defined — DDRPHYC DfiInitCompleteShadow register
  [0] DFIINITCOMPLETESHADOW — This bit presents a read-only view (a shadow) of DfiInitComplete which is used by the sequencer to control the state of dfi_init_complete.
